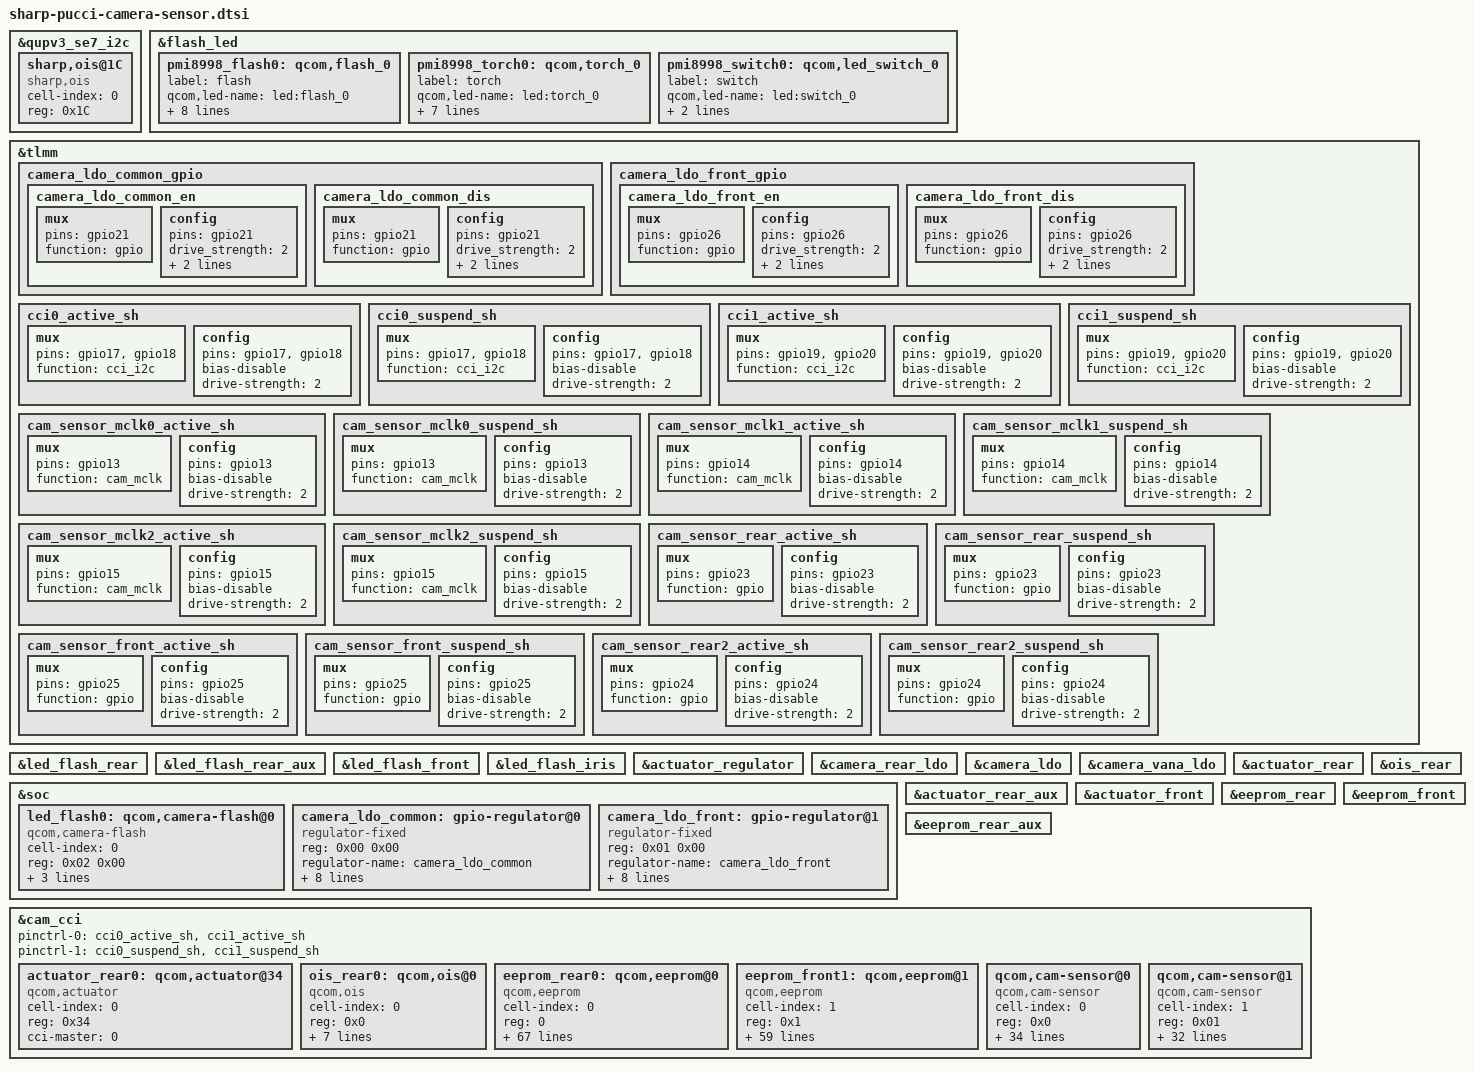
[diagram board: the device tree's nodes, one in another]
/*
 * Copyright (c) 2016, The Linux Foundation. All rights reserved.
 *
 * This program is free software; you can redistribute it and/or modify
 * it under the terms of the GNU General Public License version 2 and
 * only version 2 as published by the Free Software Foundation.
 *
 * This program is distributed in the hope that it will be useful,
 * but WITHOUT ANY WARRANTY; without even the implied warranty of
 * MERCHANTABILITY or FITNESS FOR A PARTICULAR PURPOSE.  See the
 * GNU General Public License for more details.
 */

&qupv3_se7_i2c {
	sharp,ois@1C {
		cell-index = <0>;
		reg = <0x1C>;
		compatible = "sharp,ois";
	};
};

&flash_led{
	/delete-node/ qcom,flash_0;
	/delete-node/ qcom,torch_0;
	/delete-node/ qcom,led_switch_0;
	/delete-node/ qcom,flash_1;
	/delete-node/ qcom,torch_1;
	/delete-node/ qcom,flash_2;
	/delete-node/ qcom,torch_2;
	/delete-node/ qcom,led_switch_1;

	pmi8998_flash0: qcom,flash_0 {
		label = "flash";
		qcom,led-name = "led:flash_0";
		qcom,max-current = <1200>;
		qcom,default-led-trigger = "flash0_trigger";
		qcom,id = <0>;
		qcom,current-ma = <1200>;
		qcom,duration-ms = <500>;
		qcom,ires-ua = <12500>;
		qcom,hdrm-voltage-mv = <325>;
		qcom,hdrm-vol-hi-lo-win-mv = <100>;
	};

	pmi8998_torch0: qcom,torch_0 {
		label = "torch";
		qcom,led-name = "led:torch_0";
		qcom,max-current = <250>;
		qcom,default-led-trigger = "torch0_trigger";
		qcom,id = <0>;
		qcom,current-ma = <25>;
		qcom,ires-ua = <12500>;
		qcom,hdrm-voltage-mv = <325>;
		qcom,hdrm-vol-hi-lo-win-mv = <100>;
	};

	pmi8998_switch0: qcom,led_switch_0 {
		label = "switch";
		qcom,led-name = "led:switch_0";
		qcom,led-mask = <3>;
		qcom,default-led-trigger = "switch0_trigger";
	};
};

&tlmm {
		camera_ldo_common_gpio {
			camera_ldo_common_en: camera_ldo_common_en {
				mux {
					pins = "gpio21";
					function = "gpio";
				};

				config {
					pins = "gpio21";
					drive_strength = <2>;
					output-high;
					bias-disable;
				};
			};

			camera_ldo_common_dis: camera_ldo_common_dis {
				mux {
					pins = "gpio21";
					function = "gpio";
				};

				config {
					pins = "gpio21";
					drive_strength = <2>;
					output-low;
					bias-disable;
				};
			};
		};
		
		camera_ldo_front_gpio {
			camera_ldo_front_en: camera_ldo_front_en {
				mux {
					pins = "gpio26";
					function = "gpio";
				};

				config {
					pins = "gpio26";
					drive_strength = <2>;
					output-high;
					bias-disable;
				};
			};

			camera_ldo_front_dis: camera_ldo_front_dis {
				mux {
					pins = "gpio26";
					function = "gpio";
				};

				config {
					pins = "gpio26";
					drive_strength = <2>;
					output-low;
					bias-disable;
				};
			};
		};
};

&led_flash_rear {
	/delete-property/ cell-index;
	/delete-property/ reg;
	/delete-property/ compatible;
	/delete-property/ flash-source;
	/delete-property/ torch-source;
	/delete-property/ switch-source;
	/delete-property/ status;
};

&led_flash_rear_aux {
	/delete-property/ cell-index;
	/delete-property/ reg;
	/delete-property/ compatible;
	/delete-property/ flash-source;
	/delete-property/ torch-source;
	/delete-property/ switch-source;
	/delete-property/ status;
};

&led_flash_front {
	/delete-property/ cell-index;
	/delete-property/ reg;
	/delete-property/ compatible;
	/delete-property/ flash-source;
	/delete-property/ torch-source;
	/delete-property/ switch-source;
	/delete-property/ status;
};

&led_flash_iris {
	/delete-property/ cell-index;
	/delete-property/ reg;
	/delete-property/ compatible;
	/delete-property/ flash-source;
	/delete-property/ torch-source;
	/delete-property/ switch-source;
	/delete-property/ status;
};

&actuator_regulator {
	/delete-property/ compatible;
	/delete-property/ reg;
	/delete-property/ regulator-name;
	/delete-property/ regulator-min-microvolt;
	/delete-property/ regulator-max-microvolt;
	/delete-property/ regulator-enable-ramp-delay;
	/delete-property/ enable-active-high;
	/delete-property/ gpio;
	/delete-property/ vin-supply;
};

&camera_rear_ldo {
	/delete-property/ compatible;
	/delete-property/ reg;
	/delete-property/ regulator-name;
	/delete-property/ regulator-min-microvolt;
	/delete-property/ regulator-max-microvolt;
	/delete-property/ regulator-enable-ramp-delay;
	/delete-property/ enable-active-high;
	/delete-property/ gpio;
	/delete-property/ pinctrl-names;
	/delete-property/ pinctrl-0;
	/delete-property/ vin-supply;
};

&camera_ldo {
	/delete-property/ compatible;
	/delete-property/ reg;
	/delete-property/ regulator-name;
	/delete-property/ regulator-min-microvolt;
	/delete-property/ regulator-max-microvolt;
	/delete-property/ regulator-enable-ramp-delay;
	/delete-property/ enable-active-high;
	/delete-property/ gpio;
	/delete-property/ pinctrl-names;
	/delete-property/ pinctrl-0;
	/delete-property/ vin-supply;
};

&camera_vana_ldo {
	/delete-property/ compatible;
	/delete-property/ reg;
	/delete-property/ regulator-name;
	/delete-property/ regulator-min-microvolt;
	/delete-property/ regulator-max-microvolt;
	/delete-property/ regulator-enable-ramp-delay;
	/delete-property/ enable-active-high;
	/delete-property/ gpio;
	/delete-property/ pinctrl-names;
	/delete-property/ pinctrl-0;
	/delete-property/ vin-supply;
};

&soc {
	/delete-node/ qcom,camera-flash@0;
	/delete-node/ qcom,camera-flash@1;
	/delete-node/ qcom,camera-flash@2;
	/delete-node/ gpio-regulator@0;
	/delete-node/ gpio-regulator@1;
	/delete-node/ gpio-regulator@2;
	
	led_flash0: qcom,camera-flash@0 {
		cell-index = <0>;
		reg = <0x02 0x00>;
		compatible = "qcom,camera-flash";
		flash-source = <&pmi8998_flash0>;
		torch-source = <&pmi8998_torch0>;
		switch-source = <&pmi8998_switch0>;
		status = "ok";
	};

	camera_ldo_common: gpio-regulator@0 {
		compatible = "regulator-fixed";
		reg = <0x00 0x00>;
		regulator-name = "camera_ldo_common";
		regulator-min-microvolt = <1050000>;
		regulator-max-microvolt = <1050000>;
		regulator-enable-ramp-delay = <233>;
		enable-active-high;
		gpio = <&tlmm 21 0>;
		pinctrl-names = "default";
		pinctrl-0 = <&camera_ldo_common_en>;
		pinctrl-1 = <&camera_ldo_common_dis>;
		vin-supply = <&pm8998_s4>;
	};
	
	camera_ldo_front: gpio-regulator@1 {
		compatible = "regulator-fixed";
		reg = <0x01 0x00>;
		regulator-name = "camera_ldo_front";
		regulator-min-microvolt = <1050000>;
		regulator-max-microvolt = <1050000>;
		regulator-enable-ramp-delay = <233>;
		enable-active-high;
		gpio = <&tlmm 26 0>;
		pinctrl-names = "default";
		pinctrl-0 = <&camera_ldo_front_en>;
		pinctrl-1 = <&camera_ldo_front_dis>;
		vin-supply = <&pm8998_s4>;
	};
};

&tlmm {
	/delete-node/ cci0_active;
	/delete-node/ cci0_suspend;
	/delete-node/ cci1_active;
	/delete-node/ cci1_suspend;
	/delete-node/ cam_sensor_mclk0_active;
	/delete-node/ cam_sensor_mclk0_suspend;
	/delete-node/ cam_sensor_mclk1_active;
	/delete-node/ cam_sensor_mclk1_suspend;
	/delete-node/ cam_sensor_mclk2_active;
	/delete-node/ cam_sensor_mclk2_suspend;
	/delete-node/ cam_sensor_rear_active;
	/delete-node/ cam_sensor_rear_suspend;
	/delete-node/ cam_sensor_front_active;
	/delete-node/ cam_sensor_front_suspend;
	/delete-node/ cam_sensor_rear2_active;
	/delete-node/ cam_sensor_rear2_suspend;

		cci0_active_sh: cci0_active_sh {
			mux {
				/* CLK, DATA */
				pins = "gpio17","gpio18"; // Only 2
				function = "cci_i2c";
			};

			config {
				pins = "gpio17","gpio18";
				bias-disable; /* No PULL */
				drive-strength = <2>; /* 2 MA */
			};
		};

		cci0_suspend_sh: cci0_suspend_sh {
			mux {
				/* CLK, DATA */
				pins = "gpio17","gpio18";
				function = "cci_i2c";
			};

			config {
				pins = "gpio17","gpio18";
				bias-disable; /* No PULL */
				drive-strength = <2>; /* 2 MA */
			};
		};

		cci1_active_sh: cci1_active_sh {
			mux {
				/* CLK, DATA */
				pins = "gpio19","gpio20";
				function = "cci_i2c";
			};

			config {
				pins = "gpio19","gpio20";
				bias-disable; /* No PULL */
				drive-strength = <2>; /* 2 MA */
			};
		};

		cci1_suspend_sh: cci1_suspend_sh {
			mux {
				/* CLK, DATA */
				pins = "gpio19","gpio20";
				function = "cci_i2c";
			};

			config {
				pins = "gpio19","gpio20";
				bias-disable; /* No PULL */
				drive-strength = <2>; /* 2 MA */
			};
		};

		cam_sensor_mclk0_active_sh: cam_sensor_mclk0_active_sh {
			/* MCLK0 */
			mux {
				pins = "gpio13";
				function = "cam_mclk";
			};

			config {
				pins = "gpio13";
				bias-disable; /* No PULL */
				drive-strength = <2>; /* 2 MA */
			};
		};

		cam_sensor_mclk0_suspend_sh: cam_sensor_mclk0_suspend_sh {
			/* MCLK0 */
			mux {
				pins = "gpio13";
				function = "cam_mclk";
			};

			config {
				pins = "gpio13";
				bias-disable; /* No PULL */
				drive-strength = <2>; /* 2 MA */
			};
		};

		cam_sensor_mclk1_active_sh: cam_sensor_mclk1_active_sh {
			/* MCLK1 */
			mux {
				pins = "gpio14";
				function = "cam_mclk";
			};

			config {
				pins = "gpio14";
				bias-disable; /* No PULL */
				drive-strength = <2>; /* 2 MA */
			};
		};

		cam_sensor_mclk1_suspend_sh: cam_sensor_mclk1_suspend_sh {
			/* MCLK1 */
			mux {
				pins = "gpio14";
				function = "cam_mclk";
			};

			config {
				pins = "gpio14";
				bias-disable; /* No PULL */
				drive-strength = <2>; /* 2 MA */
			};
		};

		cam_sensor_mclk2_active_sh: cam_sensor_mclk2_active_sh {
			/* MCLK1 */
			mux {
				/* CLK, DATA */
				pins = "gpio15";
				function = "cam_mclk";
			};

			config {
				pins = "gpio15";
				bias-disable; /* No PULL */
				drive-strength = <2>; /* 2 MA */
			};
		};

		cam_sensor_mclk2_suspend_sh: cam_sensor_mclk2_suspend_sh {
			/* MCLK1 */
			mux {
				/* CLK, DATA */
				pins = "gpio15";
				function = "cam_mclk";
			};

			config {
				pins = "gpio15";
				bias-disable; /* No PULL */
				drive-strength = <2>; /* 2 MA */
			};
		};

		cam_sensor_rear_active_sh: cam_sensor_rear_active_sh {
			/* RESET, AVDD LDO */
			mux {
				pins = "gpio23";
				function = "gpio";
			};

			config {
				pins = "gpio23";
				bias-disable; /* No PULL */
				drive-strength = <2>; /* 2 MA */
			};
		};

		cam_sensor_rear_suspend_sh: cam_sensor_rear_suspend_sh {
			/* RESET, AVDD LDO */
			mux {
				pins = "gpio23";
				function = "gpio";
			};

			config {
				pins = "gpio23";
				bias-disable; /* No PULL */
				drive-strength = <2>; /* 2 MA */
			};
		};

		cam_sensor_front_active_sh: cam_sensor_front_active_sh {
			/* RESET  AVDD_LDO*/
			mux {
				pins = "gpio25";
				function = "gpio";
			};

			config {
				pins = "gpio25";
				bias-disable; /* No PULL */
				drive-strength = <2>; /* 2 MA */
			};
		};

		cam_sensor_front_suspend_sh: cam_sensor_front_suspend_sh {
			/* RESET */
			mux {
				pins = "gpio25";
				function = "gpio";
			};

			config {
				pins = "gpio25";
				bias-disable; /* No PULL */
				drive-strength = <2>; /* 2 MA */
			};
		};

		cam_sensor_rear2_active_sh: cam_sensor_rear2_active_sh {
			/* RESET, STANDBY */
			mux {
				pins = "gpio24";
				function = "gpio";
			};

			config {
				pins = "gpio24";
				bias-disable; /* No PULL */
				drive-strength = <2>; /* 2 MA */
			};
		};

		cam_sensor_rear2_suspend_sh: cam_sensor_rear2_suspend_sh {
			/* RESET, STANDBY */
			mux {
				pins = "gpio24";
				function = "gpio";
			};
			config {
				pins = "gpio24";
				bias-disable; /* No PULL */
				drive-strength = <2>; /* 2 MA */
			};
		};
};

&actuator_rear {
	/delete-property/ cell-index;
	/delete-property/ reg;
	/delete-property/ compatible;
	/delete-property/ cci-master;
	/delete-property/ cam_vaf-supply;
	/delete-property/ regulator-names;
	/delete-property/ rgltr-cntrl-support;
	/delete-property/ rgltr-min-voltage;
	/delete-property/ rgltr-max-voltage;
	/delete-property/ rgltr-load-current;
};

&actuator_rear_aux {
	/delete-property/ cell-index;
	/delete-property/ reg;
	/delete-property/ compatible;
	/delete-property/ cci-master;
	/delete-property/ cam_vaf-supply;
	/delete-property/ regulator-names;
	/delete-property/ rgltr-cntrl-support;
	/delete-property/ rgltr-min-voltage;
	/delete-property/ rgltr-max-voltage;
	/delete-property/ rgltr-load-current;
};

&actuator_front {
	/delete-property/ cell-index;
	/delete-property/ reg;
	/delete-property/ compatible;
	/delete-property/ cci-master;
	/delete-property/ cam_vaf-supply;
	/delete-property/ regulator-names;
	/delete-property/ rgltr-cntrl-support;
	/delete-property/ rgltr-min-voltage;
	/delete-property/ rgltr-max-voltage;
	/delete-property/ rgltr-load-current;
};

&ois_rear {
	/delete-property/ cell-index;
	/delete-property/ reg;
	/delete-property/ compatible;
	/delete-property/ cci-master;
	/delete-property/ cam_vaf-supply;
	/delete-property/ regulator-names;
	/delete-property/ rgltr-cntrl-support;
	/delete-property/ rgltr-min-voltage;
	/delete-property/ rgltr-max-voltage;
	/delete-property/ rgltr-load-current;
	/delete-property/ status;
};

&eeprom_rear {
	/delete-property/ cell-index;
	/delete-property/ reg;
	/delete-property/ compatible;
	/delete-property/ cam_vio-supply;
	/delete-property/ cam_vana-supply;
	/delete-property/ cam_vdig-supply;
	/delete-property/ cam_clk-supply;
	/delete-property/ cam_vaf-supply;
	/delete-property/ regulator-names;
	/delete-property/ rgltr-cntrl-support;
	/delete-property/ rgltr-min-voltage;
	/delete-property/ rgltr-max-voltage;
	/delete-property/ rgltr-load-current;
	/delete-property/ gpio-no-mux;
	/delete-property/ pinctrl-names;
	/delete-property/ pinctrl-0;
	/delete-property/ pinctrl-1;
	/delete-property/ gpios;
	/delete-property/ gpio-reset;
	/delete-property/ gpio-vana;
	/delete-property/ gpio-req-tbl-num;
	/delete-property/ gpio-req-tbl-flags;
	/delete-property/ gpio-req-tbl-label;
	/delete-property/ sensor-position;
	/delete-property/ sensor-mode;
	/delete-property/ cci-master;
	/delete-property/ status;
	/delete-property/ clocks;
	/delete-property/ clock-names;
	/delete-property/ clock-cntl-level;
	/delete-property/ clock-rates;
};

&eeprom_rear_aux {
	/delete-property/ cell-index;
	/delete-property/ reg;
	/delete-property/ compatible;
	/delete-property/ cam_vdig-supply;
	/delete-property/ cam_vio-supply;
	/delete-property/ cam_vana-supply;
	/delete-property/ cam_clk-supply;
	/delete-property/ cam_vaf-supply;
	/delete-property/ regulator-names;
	/delete-property/ rgltr-cntrl-support;
	/delete-property/ rgltr-min-voltage;
	/delete-property/ rgltr-max-voltage;
	/delete-property/ rgltr-load-current;
	/delete-property/ gpio-no-mux;
	/delete-property/ pinctrl-names;
	/delete-property/ pinctrl-0;
	/delete-property/ pinctrl-1;
	/delete-property/ gpios;
	/delete-property/ gpio-reset;
	/delete-property/ gpio-vana;
	/delete-property/ gpio-req-tbl-num;
	/delete-property/ gpio-req-tbl-flags;
	/delete-property/ gpio-req-tbl-label;
	/delete-property/ sensor-position;
	/delete-property/ sensor-mode;
	/delete-property/ cci-master;
	/delete-property/ status;
	/delete-property/ clocks;
	/delete-property/ clock-names;
	/delete-property/ clock-cntl-level;
	/delete-property/ clock-rates;
};

&eeprom_front {
	/delete-property/ cell-index;
	/delete-property/ reg;
	/delete-property/ compatible;
	/delete-property/ cam_vio-supply;
	/delete-property/ cam_vana-supply;
	/delete-property/ cam_vdig-supply;
	/delete-property/ cam_clk-supply;
	/delete-property/ cam_vaf-supply;
	/delete-property/ regulator-names;
	/delete-property/ rgltr-cntrl-support;
	/delete-property/ rgltr-min-voltage;
	/delete-property/ rgltr-max-voltage;
	/delete-property/ rgltr-load-current;
	/delete-property/ gpio-no-mux;
	/delete-property/ pinctrl-names;
	/delete-property/ pinctrl-0;
	/delete-property/ pinctrl-1;
	/delete-property/ gpios;
	/delete-property/ gpio-reset;
	/delete-property/ gpio-vana;
	/delete-property/ gpio-req-tbl-num;
	/delete-property/ gpio-req-tbl-flags;
	/delete-property/ gpio-req-tbl-label;
	/delete-property/ sensor-position;
	/delete-property/ sensor-mode;
	/delete-property/ cci-master;
	/delete-property/ status;
	/delete-property/ clocks;
	/delete-property/ clock-names;
	/delete-property/ clock-cntl-level;
	/delete-property/ clock-rates;
};

&cam_cci {
	/delete-property/ pinctrl-names;
	/delete-property/ pinctrl-1;
	/delete-property/ pinctrl-1;
	
	pinctrl-names = "cam_default", "cam_suspend";
	pinctrl-0 = <&cci0_active_sh &cci1_active_sh>;
	pinctrl-1 = <&cci0_suspend_sh &cci1_suspend_sh>;
};

&cam_cci {
	/delete-node/ qcom,cam-sensor@0;
	/delete-node/ qcom,cam-sensor@1;
	/delete-node/ qcom,cam-sensor@2;
	/delete-node/ qcom,cam-sensor@3;
	/delete-node/ qcom,actuator@0;
	/delete-node/ qcom,actuator@1;
	/delete-node/ qcom,actuator@2;
	/delete-node/ qcom,ois@0;
	/delete-node/ qcom,eeprom@0;
	/delete-node/ qcom,eeprom@1;
	/delete-node/ qcom,eeprom@2;
	
    actuator_rear0: qcom,actuator@34 {
        cell-index = <0>;
        reg = <0x34>;
        compatible = "qcom,actuator";
        cci-master = <0>;
    };

	ois_rear0: qcom,ois@0 {
		cell-index = <0>;
		reg = <0x0>;
		compatible = "qcom,ois";
		cci-master = <0>;
		cam_vaf-supply = <&pm8998_s4>;
		regulator-names = "cam_vaf";
		rgltr-cntrl-support;
		rgltr-min-voltage = <1800000>;
		rgltr-max-voltage = <1800000>;
		rgltr-load-current = <0>;
		status = "ok";
	};
	
	eeprom_rear0: qcom,eeprom@0 {
		cell-index = <0>;
		reg = <0>;
		eeprom-name = "sony_imx318";
		compatible = "qcom,eeprom";

		i2c-freq-mode = <1>;
		slave-addr = <0xa0>;
		num-blocks = <6>;

		page0 = <0 0 0 0 0 0>;
		pageen0 = <0 0 0 0 0 0>;
		poll0 = <0 0 0 0 0 0>;
		mem0 = <0x800 0x00 2 0x00 1 0>;
		saddr0 = <0xa0>;

		page1 = <1 0x0136 2 0x06 1 0>;
		pageen1 = <0 0 0 0 0 0>;
		poll1 = <0 0 0 0 0 0>;
		mem1 = <0 0 0 0 0 0>;
		saddr1 = <0x34>;

		page2 = <1 0x0137 2 0x40 1 0>;
		pageen2 = <0 0 0 0 0 0>;
		poll2 = <0 0 0 0 0 0>;
		mem2 = <0 0 0 0 0 0>;
		saddr2 = <0x34>;

		page3 = <1 0x0A02 2 0x14 1 0>;
		pageen3 = <1 0x0A00 2 0x01 1 0>;
		poll3 = <1 0x0A01 2 0x01 1 99>;
		mem3 = <0xD 0x0A37 2 0x00 1 0>;
		saddr3 = <0x34>;

		page4 = <1 0x0A02 2 0x15 1 0>;
		pageen4 = <1 0x0A00 2 0x01 1 0>;
		poll4 = <1 0x0A01 2 0x01 1 99>;
		mem4 = <0x40 0x0A04 2 0x00 1 0>;
		saddr4 = <0x34>;

		page5 = <1 0x0A02 2 0x16 1 0>;
		pageen5 = <1 0x0A00 2 0x01 1 0>;
		poll5 = <1 0x0A01 2 0x01 1 99>;
		mem5 = <0x13 0x0A04 2 0x00 1 0>;
		saddr5 = <0x34>;

		cam_vio-supply = <&pm8998_lvs1>;
		cam_vana-supply = <&pm8998_s5>;
		cam_vdig-supply = <&pm8998_l21>;
		cam_vaf-supply = <&camera_ldo_common>;
		cam_clk-supply = <&titan_top_gdsc>;
		regulator-names = "cam_vio", "cam_vana", "cam_vdig", "cam_vaf",
			"cam_clk";
		rgltr-cntrl-support;
		rgltr-min-voltage = <0 1904000 2952000 1050000 0>;
		rgltr-max-voltage = <0 2040000 2952000 1050000 0>;
		rgltr-load-current = <0 105000 80000 105000 0>;
		gpio-no-mux = <0>;
		pinctrl-names = "cam_default", "cam_suspend";
		pinctrl-0 = <&cam_sensor_mclk0_active_sh
				&cam_sensor_rear_active_sh>;
		pinctrl-1 = <&cam_sensor_mclk0_suspend_sh
				&cam_sensor_rear_suspend_sh>;
		gpios = <&tlmm 13 0>,
			<&tlmm 23 0>;
		gpio-reset = <1>;
		gpio-req-tbl-num = <0 1>;
		gpio-req-tbl-flags = <1 0>;
		gpio-req-tbl-label = "CAMIF_MCLK0",
					"CAM_RESET0";
		sensor-position = <0>;
		sensor-mode = <0>;
		cci-master = <0>;
		status = "ok";
		clocks = <&clock_camcc CAM_CC_MCLK0_CLK>;
		clock-names = "cam_clk";
		clock-cntl-level = "turbo";
		clock-rates = <24000000>;
		
		qcom,cam-power-seq-type = "cam_reset", "cam_vana", "cam_vdig", "cam_vaf", "cam_vio", "cam_clk", "cam_reset";
		qcom,cam-power-seq-cfg-val = <0 1 1 1 1 6060606 1>;
		qcom,cam-power-seq-delay = <0 0 0 0 0 0 18>;
	};

	eeprom_front1: qcom,eeprom@1 {
		cell-index = <1>;
		reg = <0x1>;
		eeprom-name = "omuni_ov8856";
		compatible = "qcom,eeprom";
		
		i2c-freq-mode = <1>;
		slave-addr = <0x20>;
		num-blocks = <5>;

		page0 = <1 0x0100 2 0x01 1 0>;
		pageen0 = <0 0 0 0 0 0>;
		poll0 = <0 0 0 0 0 0>;
		mem0 = <0 0 0 0 0 0>;
		saddr0 = <0x20>;

		page1 = <1 0x5002 2 0x20 1 0>;
		pageen1 = <0 0 0 0 0 0>;
		poll1 = <0 0 0 0 0 0>;
		mem1 = <0 0 0 0 0 0>;
		saddr1 = <0x20>;

		page2 = <1 0x3d84 2 0x80 1 20>;
		pageen2 = <1 0x3d81 2 0x01 1 20>;
		poll2 = <0 0 0 0 0 0>;
		mem2 = <0x1FF 0x7000 2 0x00 1 0>;
		saddr2 = <0x20>;

		page3 = <0 0 0 0 0 0>;
		pageen3 = <0 0 0 0 0 0>;
		poll3 = <0 0 0 0 0 0>;
		mem3 = <0x1 0x3d81 2 0x00 1 0>;
		saddr3 = <0x20>;

		page4 = <1 0x5002 2 0x28 1 0>;
		pageen4 = <1 0x0100 2 0x00 1 0>;
		poll4 = <0 0 0 0 0 0>;
		mem4 = <0 0 0 0 0 0>;
		saddr4 = <0x20>;

		cam_vio-supply = <&camera_ldo_front>;
		cam_vana-supply = <&pm8998_lvs1>;
		cam_vdig-supply = <&camera_ldo_common>;
		cam_clk-supply = <&titan_top_gdsc>;
		regulator-names = "cam_vio", "cam_vana", "cam_vdig",
			"cam_clk";
		rgltr-cntrl-support;
		rgltr-min-voltage = <1050000 0 1050000 0>;
		rgltr-max-voltage = <1050000 0 1050000 0>;
		rgltr-load-current = <105000 0 105000 0>;
		gpio-no-mux = <0>;
		pinctrl-names = "cam_default", "cam_suspend";
		pinctrl-0 = <&cam_sensor_mclk2_active_sh
				 &cam_sensor_front_active_sh>;
		pinctrl-1 = <&cam_sensor_mclk2_suspend_sh
				 &cam_sensor_front_suspend_sh>;
		gpios = <&tlmm 15 0>,
			<&tlmm 25 0>;
		gpio-reset = <1>;
		gpio-req-tbl-num = <0 1>;
		gpio-req-tbl-flags = <1 0>;
		gpio-req-tbl-label = "CAMIF_MCLK2",
					"CAM_RESET2";
		sensor-position = <0>;
		sensor-mode = <0>;
		cci-master = <0>;
		status = "ok";
		clocks = <&clock_camcc CAM_CC_MCLK2_CLK>;
		clock-names = "cam_clk";
		clock-cntl-level = "turbo";
		clock-rates = <24000000>;
		
		qcom,cam-power-seq-type = "cam_reset", "cam_vana", "cam_vdig", "cam_vio", "cam_clk", "cam_reset";
		qcom,cam-power-seq-cfg-val = <0 1 1 1 6000000 1>;
		qcom,cam-power-seq-delay = <0 0 0 0 0 11>;
	};

	qcom,cam-sensor@0 {
		cell-index = <0>;
		compatible = "qcom,cam-sensor";
		reg = <0x0>;
		csiphy-sd-index = <2>;
		sensor-position-roll = <90>;
		sensor-position-pitch = <0>;
		sensor-position-yaw = <180>;
		led-flash-src = <&led_flash0>;
		actuator-src = <&actuator_rear0>;
		ois-src = <&ois_rear0>;
		eeprom-src = <&eeprom_rear0>;
		cam_vio-supply = <&pm8998_lvs1>;
		cam_vana-supply = <&pm8998_s5>;
		cam_vdig-supply = <&pm8998_l21>;
		cam_vaf-supply = <&camera_ldo_common>;
		cam_clk-supply = <&titan_top_gdsc>;
		regulator-names = "cam_vio", "cam_vana", "cam_vdig", "cam_vaf",
			"cam_clk";
		rgltr-cntrl-support;
		rgltr-min-voltage = <0 1904000 2952000 1050000 0>;
		rgltr-max-voltage = <0 2040000 2952000 1050000 0>;
		rgltr-load-current = <0 105000 80000 105000 0>;
		gpio-no-mux = <0>;
		pinctrl-names = "cam_default", "cam_suspend";
		pinctrl-0 = <&cam_sensor_mclk0_active_sh
				&cam_sensor_rear_active_sh>;
		pinctrl-1 = <&cam_sensor_mclk0_suspend_sh
				&cam_sensor_rear_suspend_sh>;
		gpios = <&tlmm 13 0>,
			<&tlmm 23 0>;
		gpio-reset = <1>;
		gpio-req-tbl-num = <0 1>;
		gpio-req-tbl-flags = <1 0>;
		gpio-req-tbl-label = "CAMIF_MCLK0",
					"CAM_RESET0";
		sensor-mode = <0>;
		cci-master = <0>;
		status = "ok";
		clocks = <&clock_camcc CAM_CC_MCLK0_CLK>;
		clock-names = "cam_clk";
		clock-cntl-level = "turbo";
		clock-rates = <24000000>;
	};

	qcom,cam-sensor@1 {
		cell-index = <1>;
		compatible = "qcom,cam-sensor";
		reg = <0x01>;
		csiphy-sd-index = <1>;
		sensor-position-roll = <270>;
		sensor-position-pitch = <0>;
		sensor-position-yaw = <0>;
//		actuator-src = <&actuator_front>;
		actuator-src = <0>;
//		led-flash-src = <&led_flash_front>;
		led-flash-src = <0>;
		eeprom-src = <&eeprom_front1>;
		cam_vio-supply = <&camera_ldo_front>;
		cam_vana-supply = <&pm8998_lvs1>;
		cam_vdig-supply = <&camera_ldo_common>;
		cam_clk-supply = <&titan_top_gdsc>;
		regulator-names = "cam_vio", "cam_vana", "cam_vdig",
			"cam_clk";
		rgltr-cntrl-support;
		rgltr-min-voltage = <1050000 0 1050000 0>;
		rgltr-max-voltage = <1050000 0 1050000 0>;
		rgltr-load-current = <105000 0 105000 0>;
		gpio-no-mux = <0>;
		pinctrl-names = "cam_default", "cam_suspend";
		pinctrl-0 = <&cam_sensor_mclk2_active_sh
				 &cam_sensor_front_active_sh>;
		pinctrl-1 = <&cam_sensor_mclk2_suspend_sh
				 &cam_sensor_front_suspend_sh>;
		gpios = <&tlmm 15 0>,
			<&tlmm 25 0>;
		gpio-reset = <1>;
		gpio-req-tbl-num = <0 1>;
		gpio-req-tbl-flags = <1 0>;
		gpio-req-tbl-label = "CAMIF_MCLK2",
					"CAM_RESET2";
		sensor-mode = <0>;
		cci-master = <0>;
		status = "ok";
		clocks = <&clock_camcc CAM_CC_MCLK2_CLK>;
		clock-names = "cam_clk";
		clock-cntl-level = "turbo";
		clock-rates = <24000000>;
	};

};
